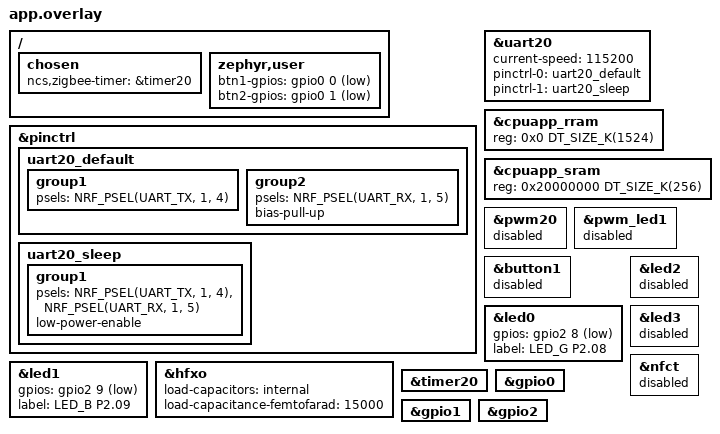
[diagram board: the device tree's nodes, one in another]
/*
 * zigbee_demo — eink_tag rev_b GPIO + Zigbee R23 nRF54L15 分区/定时器
 *
 * UART20: TX=P1.04  RX=P1.05
 * LED_G/B: P2.08 / P2.09 ACTIVE_LOW
 * BTN1/2:  P0.00 / P0.01 ACTIVE_LOW + PULL_UP
 */

#include <zephyr/dt-bindings/gpio/gpio.h>
#include <zephyr/dt-bindings/pinctrl/nrf-pinctrl.h>

/* 分区由 Partition Manager + ncs-zigbee pm.yml.zboss 生成（NCS 3.2 路径） */

&pinctrl {
	uart20_default: uart20_default {
		group1 {
			psels = <NRF_PSEL(UART_TX, 1, 4)>;
		};
		group2 {
			psels = <NRF_PSEL(UART_RX, 1, 5)>;
			bias-pull-up;
		};
	};

	uart20_sleep: uart20_sleep {
		group1 {
			psels = <NRF_PSEL(UART_TX, 1, 4)>,
				<NRF_PSEL(UART_RX, 1, 5)>;
			low-power-enable;
		};
	};
};

&uart20 {
	status = "okay";
	current-speed = <115200>;
	pinctrl-0 = <&uart20_default>;
	pinctrl-1 = <&uart20_sleep>;
	pinctrl-names = "default", "sleep";
};

/* 无 FLPR：恢复全片 RRAM/SRAM */
&cpuapp_rram {
	reg = <0x0 DT_SIZE_K(1524)>;
};

&cpuapp_sram {
	reg = <0x20000000 DT_SIZE_K(256)>;
	ranges = <0x0 0x20000000 0x40000>;
};

&pwm20 {
	status = "disabled";
};

&pwm_led1 {
	status = "disabled";
};

&button1 {
	status = "disabled";
};

&led0 {
	gpios = <&gpio2 8 GPIO_ACTIVE_LOW>;
	label = "LED_G P2.08";
};

&led1 {
	gpios = <&gpio2 9 GPIO_ACTIVE_LOW>;
	label = "LED_B P2.09";
};

&led2 {
	status = "disabled";
};

&led3 {
	status = "disabled";
};

&nfct {
	status = "disabled";
};

&hfxo {
	status = "okay";
	load-capacitors = "internal";
	load-capacitance-femtofarad = <15000>;
};

&timer20 {
	status = "okay";
};

&gpio0 {
	status = "okay";
};

&gpio1 {
	status = "okay";
};

&gpio2 {
	status = "okay";
};

/ {
	chosen {
		ncs,zigbee-timer = &timer20;
	};

	zephyr,user {
		btn1-gpios = <&gpio0 0 (GPIO_ACTIVE_LOW | GPIO_PULL_UP)>;
		btn2-gpios = <&gpio0 1 (GPIO_ACTIVE_LOW | GPIO_PULL_UP)>;
	};
};
